VERSION ""

NS_ :

BS_:

BU_:

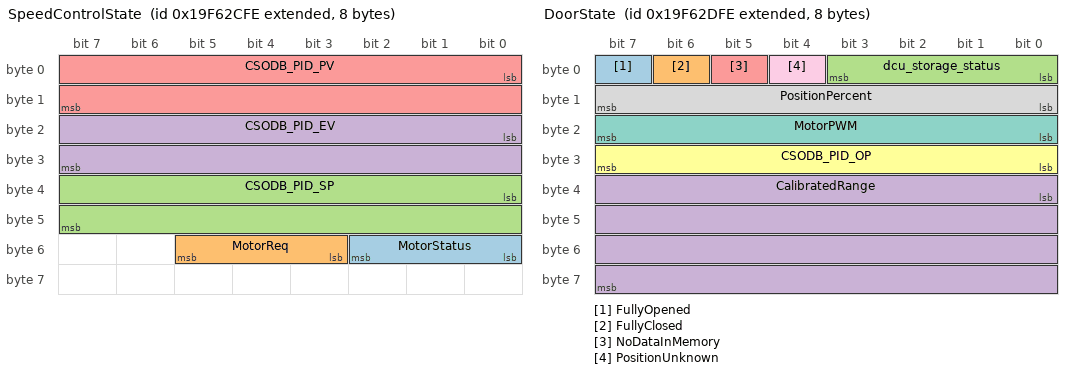
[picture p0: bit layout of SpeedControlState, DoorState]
BO_ 2583047422 SpeedControlState: 8 Vector__XXX
 SG_ MotorStatus : 48|3@1+ (1,0) [0|0] "" Vector__XXX
 SG_ MotorReq : 51|3@1+ (1,0) [0|7] "" Vector__XXX
 SG_ CSODB_PID_SP : 32|16@1- (0.1,0) [0|0] "" Vector__XXX
 SG_ CSODB_PID_EV : 16|16@1- (0.1,0) [0|0] "" Vector__XXX
 SG_ CSODB_PID_PV : 0|16@1- (0.1,0) [0|0] "" Vector__XXX

BO_ 2583047678 DoorState: 8 Vector__XXX
 SG_ FullyOpened : 7|1@1+ (1,0) [0|1] "" Vector__XXX
 SG_ FullyClosed : 6|1@1+ (1,0) [0|1] "" Vector__XXX
 SG_ dcu_storage_status : 0|4@1+ (1,0) [0|15] "" Vector__XXX
 SG_ CalibratedRange : 32|32@1- (1,0) [-2147483648|2147483647] "" Vector__XXX
 SG_ NoDataInMemory : 5|1@1+ (1,0) [0|1] "" Vector__XXX
 SG_ CSODB_PID_OP : 24|8@1+ (1,0) [0|100] "%" Vector__XXX
 SG_ MotorPWM : 16|8@1+ (1,0) [0|100] "%" Vector__XXX
 SG_ PositionPercent : 8|8@1+ (1,0) [0|100] "%" Vector__XXX
 SG_ PositionUnknown : 4|1@1+ (1,0) [0|1] "" Vector__XXX

BA_DEF_ SG_  "SigType" ENUM  "Default","Range","RangeSigned","ASCII","Discrete","Control","ReferencePGN","DTC","StringDelimiter","StringLength","StringLengthControl","MessageCounter","MessageChecksum";
BA_DEF_ SG_  "GenSigEVName" STRING ;
BA_DEF_ SG_  "GenSigILSupport" ENUM  "No","Yes";
BA_DEF_ SG_  "GenSigSendType" ENUM  "Cyclic","OnWrite","OnWriteWithRepetition","OnChange","OnChangeWithRepetition","IfActive","IfActiveWithRepetition","NoSigSendType";
BA_DEF_ BO_  "GenMsgILSupport" ENUM  "No","Yes";
BA_DEF_ BU_  "NmStationAddress" INT 0 255;
BA_DEF_ BO_  "GenMsgSendType" ENUM  "cyclic","NotUsed","IfActive","NotUsed","NotUsed","NotUsed","NotUsed","NotUsed","noMsgSendType";
BA_DEF_ BO_  "GenMsgRequestable" INT 0 1;
BA_DEF_ BO_  "GenMsgCycleTime" INT 0 3600000;
BA_DEF_  "DBName" STRING ;
BA_DEF_  "BusType" STRING ;
BA_DEF_  "ProtocolType" STRING ;
BA_DEF_ BO_  "VFrameFormat" ENUM  "StandardCAN","ExtendedCAN","reserved","J1939PG";
BA_DEF_DEF_  "SigType" "Default";
BA_DEF_DEF_  "GenSigEVName" "Env@Nodename_@Signame";
BA_DEF_DEF_  "GenSigILSupport" "Yes";
BA_DEF_DEF_  "GenSigSendType" "NoSigSendType";
BA_DEF_DEF_  "GenMsgILSupport" "Yes";
BA_DEF_DEF_  "NmStationAddress" 254;
BA_DEF_DEF_  "GenMsgSendType" "noMsgSendType";
BA_DEF_DEF_  "GenMsgRequestable" 1;
BA_DEF_DEF_  "GenMsgCycleTime" 0;
BA_DEF_DEF_  "DBName" "";
BA_DEF_DEF_  "BusType" "CAN";
BA_DEF_DEF_  "ProtocolType" "J1939";
BA_DEF_DEF_  "VFrameFormat" "J1939PG";
BA_ "DBName" "J1939Template";
BA_ "GenMsgSendType" BO_ 2583047422 0;
BA_ "GenMsgCycleTime" BO_ 2583047422 50;
BA_ "GenMsgSendType" BO_ 2583047678 0;
BA_ "GenMsgCycleTime" BO_ 2583047678 50;
VAL_ 2583047422 MotorStatus 7 "Not available" 6 "Error" 5 "Unknown" 4 "Closing" 3 "Opening" 2 "Intermediate" 1 "Closed" 0 "Open" ;
VAL_ 2583047422 MotorReq 6 "Calibration" 7 "Not available" 3 "Close" 2 "Open" 1 "Stop" 0 "Disable" ;
